# iostm32f105xx register map
Registers are 32-bit, access not given, no defined reset value unless marked. A register's access mark holds for its fields unless they carry their own. Addresses are absolute; registers are grouped by the start of their names; [hi:lo] are bit positions; {n}, {i} and the like mark numbered series.

## DBGMCU
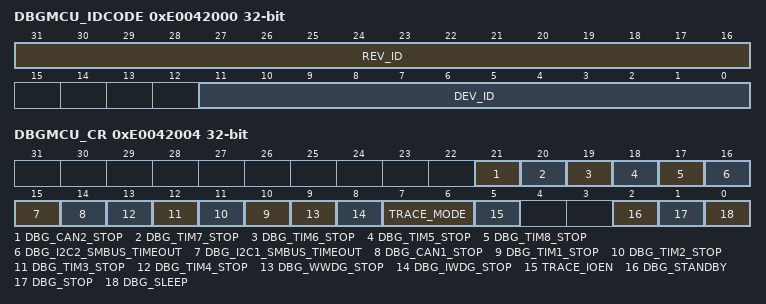
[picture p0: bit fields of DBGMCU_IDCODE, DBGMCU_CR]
0xE0042000 DBGMCU_IDCODE
  [31:16] REV_ID, [11:0] DEV_ID
0xE0042004 DBGMCU_CR
  [21] DBG_CAN2_STOP, [20] DBG_TIM7_STOP, [19] DBG_TIM6_STOP, [18] DBG_TIM5_STOP, [17] DBG_TIM8_STOP, [16] DBG_I2C2_SMBUS_TIMEOUT, [15] DBG_I2C1_SMBUS_TIMEOUT, [14] DBG_CAN1_STOP, [n+9] DBG_TIM{n}_STOP (n=1..4), [9] DBG_WWDG_STOP, [8] DBG_IWDG_STOP, [7:6] TRACE_MODE, [5] TRACE_IOEN, [2] DBG_STANDBY, [1] DBG_STOP, [0] DBG_SLEEP

## PWR
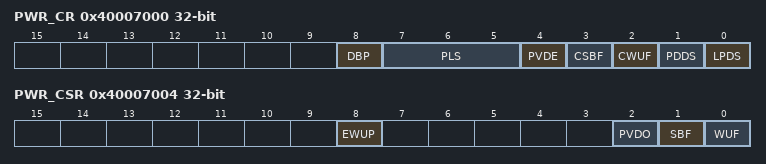
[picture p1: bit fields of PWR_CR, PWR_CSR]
0x40007000 PWR_CR
  [8] DBP, [7:5] PLS, [4] PVDE, [3] CSBF, [2] CWUF, [1] PDDS, [0] LPDS
0x40007004 PWR_CSR
  [8] EWUP, [2] PVDO, [1] SBF, [0] WUF

## RCC
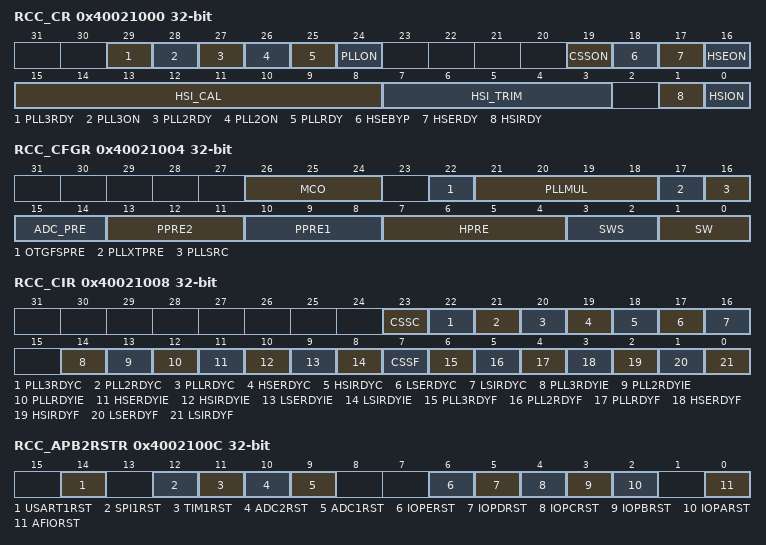
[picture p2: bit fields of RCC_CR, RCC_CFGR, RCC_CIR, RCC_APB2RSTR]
0x40021000 RCC_CR
  [29] PLL3RDY, [28] PLL3ON, [27] PLL2RDY, [26] PLL2ON, [25] PLLRDY, [24] PLLON, [19] CSSON, [18] HSEBYP, [17] HSERDY, [16] HSEON, [15:8] HSI_CAL, [7:3] HSI_TRIM, [1] HSIRDY, [0] HSION
0x40021004 RCC_CFGR
  [26:24] MCO, [22] OTGFSPRE, [21:18] PLLMUL, [17] PLLXTPRE, [16] PLLSRC, [15:14] ADC_PRE, [13:11] PPRE2, [10:8] PPRE1, [7:4] HPRE, [3:2] SWS, [1:0] SW
0x40021008 RCC_CIR
  [23] CSSC, [22] PLL3RDYC, [21] PLL2RDYC, [20] PLLRDYC, [19] HSERDYC, [18] HSIRDYC, [17] LSERDYC, [16] LSIRDYC, [14] PLL3RDYIE, [13] PLL2RDYIE, [12] PLLRDYIE, [11] HSERDYIE, [10] HSIRDYIE, [9] LSERDYIE, [8] LSIRDYIE, [7] CSSF, [6] PLL3RDYF, [5] PLL2RDYF, [4] PLLRDYF, [3] HSERDYF, [2] HSIRDYF, [1] LSERDYF, [0] LSIRDYF
0x4002100C RCC_APB2RSTR
  [14] USART1RST, [12] SPI1RST, [11] TIM1RST, [10] ADC2RST, [9] ADC1RST, [6] IOPERST, [5] IOPDRST, [4] IOPCRST, [3] IOPBRST, [2] IOPARST, [0] AFIORST
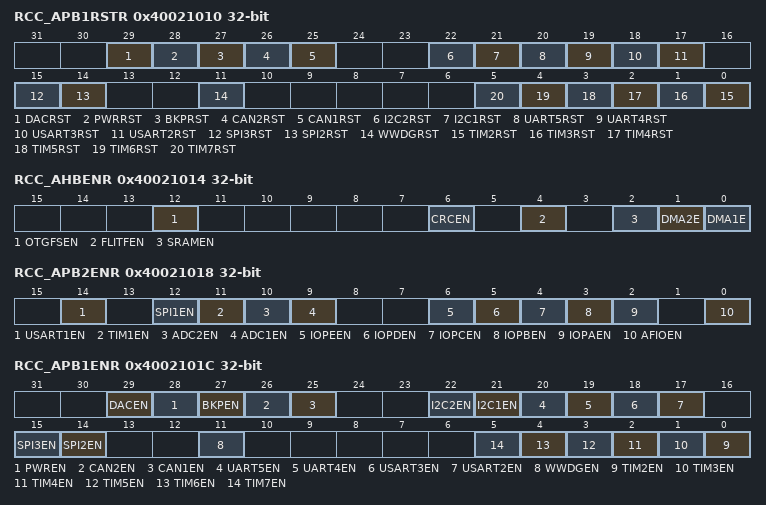
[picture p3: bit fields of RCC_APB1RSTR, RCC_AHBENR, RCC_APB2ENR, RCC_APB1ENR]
0x40021010 RCC_APB1RSTR
  [29] DACRST, [28] PWRRST, [27] BKPRST, [26] CAN2RST, [25] CAN1RST, [22] I2C2RST, [21] I2C1RST, [20] UART5RST, [19] UART4RST, [18] USART3RST, [17] USART2RST, [15] SPI3RST, [14] SPI2RST, [11] WWDGRST, [n-2] TIM{n}RST (n=2..7)
0x40021014 RCC_AHBENR
  [12] OTGFSEN, [6] CRCEN, [4] FLITFEN, [2] SRAMEN, [1] DMA2E, [0] DMA1E
0x40021018 RCC_APB2ENR
  [14] USART1EN, [12] SPI1EN, [11] TIM1EN, [10] ADC2EN, [9] ADC1EN, [6] IOPEEN, [5] IOPDEN, [4] IOPCEN, [3] IOPBEN, [2] IOPAEN, [0] AFIOEN
0x4002101C RCC_APB1ENR
  [29] DACEN, [28] PWREN, [27] BKPEN, [26] CAN2EN, [25] CAN1EN, [22] I2C2EN, [21] I2C1EN, [20] UART5EN, [19] UART4EN, [18] USART3EN, [17] USART2EN, [15] SPI3EN, [14] SPI2EN, [11] WWDGEN, [n-2] TIM{n}EN (n=2..7)
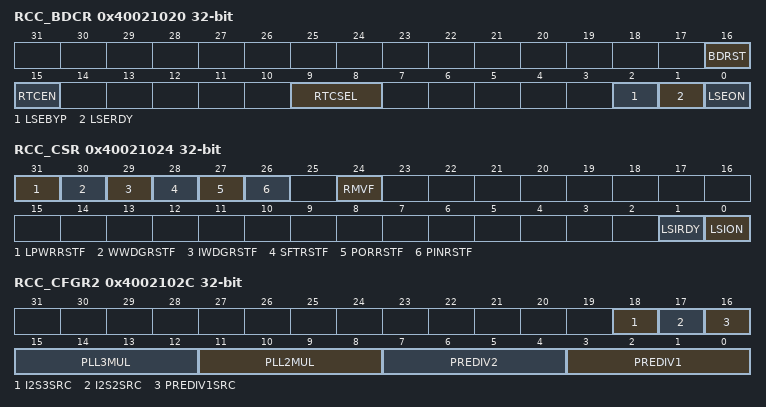
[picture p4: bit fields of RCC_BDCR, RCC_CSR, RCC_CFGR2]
0x40021020 RCC_BDCR
  [16] BDRST, [15] RTCEN, [9:8] RTCSEL, [2] LSEBYP, [1] LSERDY, [0] LSEON
0x40021024 RCC_CSR
  [31] LPWRRSTF, [30] WWDGRSTF, [29] IWDGRSTF, [28] SFTRSTF, [27] PORRSTF, [26] PINRSTF, [24] RMVF, [1] LSIRDY, [0] LSION
0x40021028 RCC_AHBRSTR
  [12] OTGFSRST
0x4002102C RCC_CFGR2
  [18] I2S3SRC, [17] I2S2SRC, [16] PREDIV1SRC, [15:12] PLL3MUL, [11:8] PLL2MUL, [7:4] PREDIV2, [3:0] PREDIV1

## GPIOA
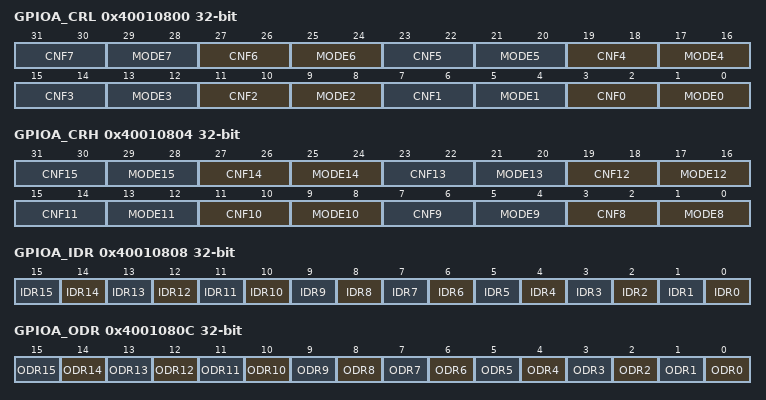
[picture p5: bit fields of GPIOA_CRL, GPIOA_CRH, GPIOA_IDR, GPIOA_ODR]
0x40010800 GPIOA_CRL
  [4n+3:4n+2] CNF{n} (n=0..7), [4n+1:4n] MODE{n} (n=0..7)
0x40010804 GPIOA_CRH
  [4n-29:4n-30] CNF{n} (n=8..15), [4n-31:4n-32] MODE{n} (n=8..15)
0x40010808 GPIOA_IDR
  [n] IDR{n} (n=0..15)
0x4001080C GPIOA_ODR
  [n] ODR{n} (n=0..15)
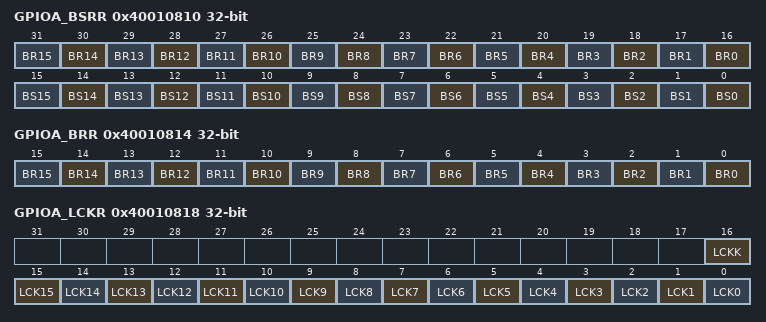
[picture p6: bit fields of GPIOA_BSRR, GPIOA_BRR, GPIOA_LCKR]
0x40010810 GPIOA_BSRR
  [n+16] BR{n} (n=0..15), [n] BS{n} (n=0..15)
0x40010814 GPIOA_BRR
  [n] BR{n} (n=0..15)
0x40010818 GPIOA_LCKR
  [16] LCKK, [n] LCK{n} (n=0..15)

## GPIOB
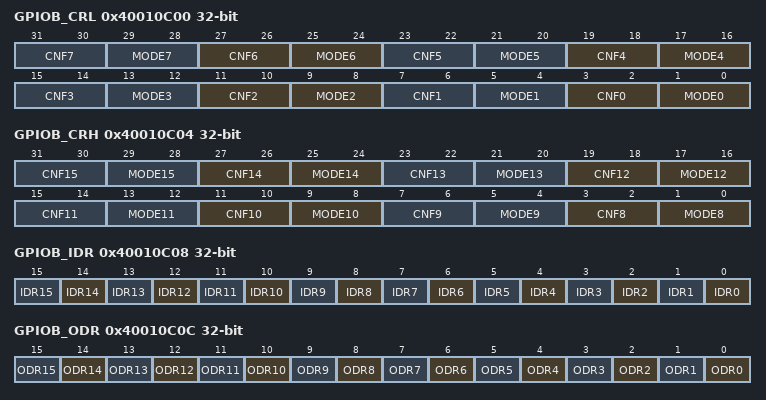
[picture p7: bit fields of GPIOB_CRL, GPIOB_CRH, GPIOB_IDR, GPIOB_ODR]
0x40010C00 GPIOB_CRL
  [4n+3:4n+2] CNF{n} (n=0..7), [4n+1:4n] MODE{n} (n=0..7)
0x40010C04 GPIOB_CRH
  [4n-29:4n-30] CNF{n} (n=8..15), [4n-31:4n-32] MODE{n} (n=8..15)
0x40010C08 GPIOB_IDR
  [n] IDR{n} (n=0..15)
0x40010C0C GPIOB_ODR
  [n] ODR{n} (n=0..15)
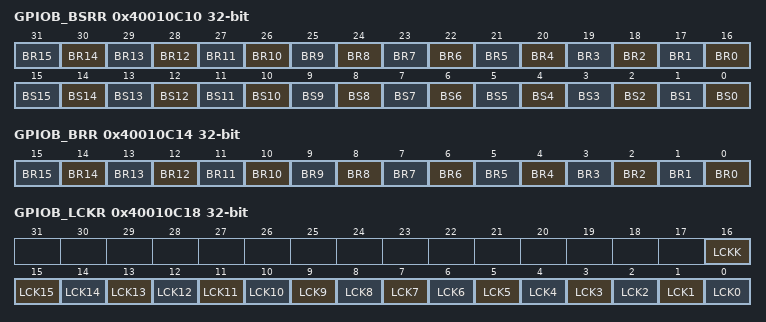
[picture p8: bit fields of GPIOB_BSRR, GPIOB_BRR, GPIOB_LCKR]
0x40010C10 GPIOB_BSRR
  [n+16] BR{n} (n=0..15), [n] BS{n} (n=0..15)
0x40010C14 GPIOB_BRR
  [n] BR{n} (n=0..15)
0x40010C18 GPIOB_LCKR
  [16] LCKK, [n] LCK{n} (n=0..15)

## GPIOC
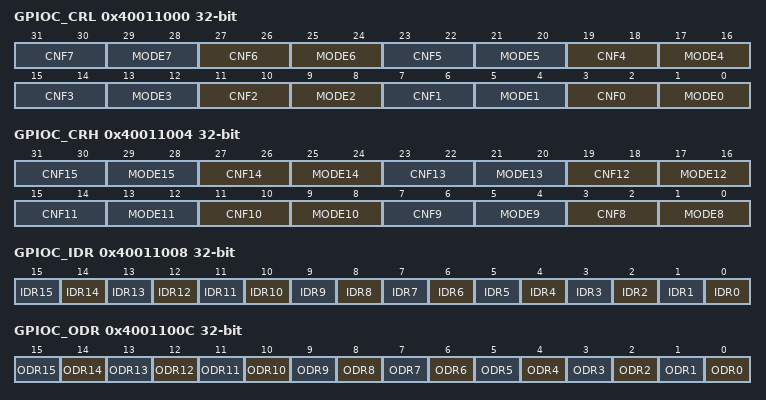
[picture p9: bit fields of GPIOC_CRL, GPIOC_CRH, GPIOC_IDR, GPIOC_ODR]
0x40011000 GPIOC_CRL
  [4n+3:4n+2] CNF{n} (n=0..7), [4n+1:4n] MODE{n} (n=0..7)
0x40011004 GPIOC_CRH
  [4n-29:4n-30] CNF{n} (n=8..15), [4n-31:4n-32] MODE{n} (n=8..15)
0x40011008 GPIOC_IDR
  [n] IDR{n} (n=0..15)
0x4001100C GPIOC_ODR
  [n] ODR{n} (n=0..15)
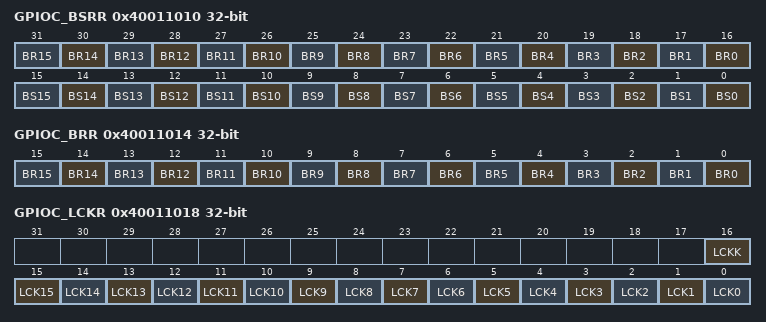
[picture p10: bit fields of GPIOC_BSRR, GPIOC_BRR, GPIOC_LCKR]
0x40011010 GPIOC_BSRR
  [n+16] BR{n} (n=0..15), [n] BS{n} (n=0..15)
0x40011014 GPIOC_BRR
  [n] BR{n} (n=0..15)
0x40011018 GPIOC_LCKR
  [16] LCKK, [n] LCK{n} (n=0..15)
